# pmg1s2 register map
Vendor: Cypress Semiconductor; Series: PMG1S2; File version: 1.0
CPU: CM0 r0p1, little endian, no MPU, no FPU, 2 interrupt priority bits
Registers are 32-bit, read-write, reset 0x0 unless marked. A register's access mark holds for its fields unless they carry their own. Offsets are from the block's base; [hi:lo] are bit positions; lines under a group give offsets from that group; {n}, {i} and the like mark numbered series; 'fields as' and 'values as' point back to an identical list; <NAME> marks a mode.

## GPIO — GPIO port control/configuration
Base 0x40040000
{0x0+0x100*i} PRT[{i}] (i=0..4) group — GPIO port registers
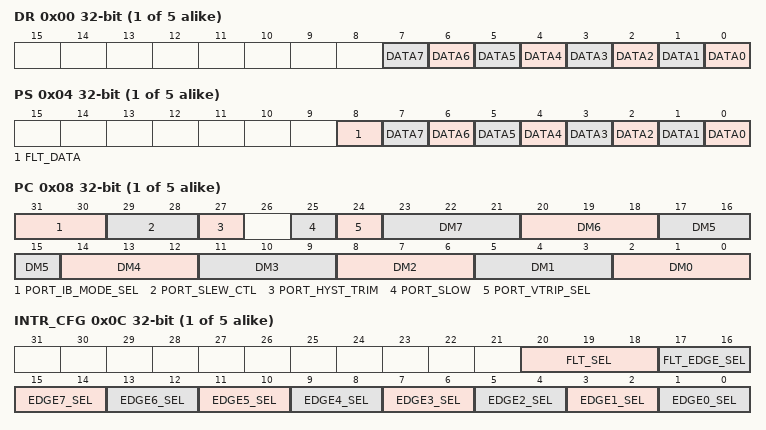
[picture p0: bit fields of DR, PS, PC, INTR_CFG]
  0x00 DR — Port output data register
    [n] DATA{n} (n=0..7) — IO pad {n} output data.
  0x04 PS ro — Port IO pad state register
    [8] FLT_DATA — Reads of this register return the logical state of the filtered pin.
    [n] DATA{n} (n=1..7) — IO pad {n} state.
    [0] DATA0 — IO pad 0 state: 1: Logic high, if the pin voltage is above the input buffer threshold, logic high. 0: Logic low, if the pin voltage is below that threshold, logic low. If the drive mode for the pin is set to high Z Analog, the pin state will read 0 independent of the voltage on the pin.
  0x08 PC — Port configuration register
    [31:30] PORT_IB_MODE_SEL — This field selects the input buffer reference. The size (1 or 2 bits) and functionality is dependent on the IO cell. For GPIOv2 IO cells, bit PORT_IB_MODE_SEL[1] is not used (GPIOv2 IO cell replaces GPIO IO cell): '0'/'2': CMOS input buffer (PORT_VTRIP_SEL is '0'), LVTTL input buffer (PORT_VTRIP_SEL is '1') '1'/'3': vcchib. For GPIO_OVTv2 and SIOv2 IO cells: '0': CMOS input buffer (PORT_VTRIP_SEL is '0'), LVTTL input buffer (PORT_VTRIP_SEL is '1') '1': vcchib. '2': OVT. '3': Reference (possibly from reference generator cell). For SIO IO cell, this field is present but not used as the SIO IO cell does not provide input buffer mode select functionality (SIOv2 IO cell will replace SIO IO cell, as soon as it is available).
    [29:28] PORT_SLEW_CTL — Slew control. Only used in the O_Z drive mode (mode 4: strong pull down, open drain): This field is intended for I2C functionality. See BROS 001-70428 for more details.
      0=HS mode (100pf < Cb < 400pF, 1.71<VDDD<5.5, Vext>3.0) FS mode (10pf<Cb<400pf,1.71<VDDD<5.5) (20-160ns); 1=HS mode (Cb<100pf,1.71<VDDD<5.5,Vext>2.8,F=1.7MHz) (10-80ns) FS+ Mode (Vext>2.8,1.71<VDDD<5.5) (20-120ns); 2=HS mode (100pf<Cb<400pf, 1.71<VDDD<5.5,Vext<3.3) (20-160ns); 3=HS mode (Cb<100pf,1.71<VDDD<5.5,Vext<=2.8,F=1.7MHz) (10-80ns) FS+ mode (Vext<=2.8,1.71<VDDD<5.5) (20-120ns)
    [27] PORT_HYST_TRIM — This field is used to improve the hysteresis (to 10 percent of vddio) of the selectable trip point input buffer. The voltage reference comes from the VREFGEN block and is only available when using the VREFGEN block: '0': <= 2.2 V input signaling Voltage. '1': > 2.2 V input signaling Voltage.
    [25] PORT_SLOW — This field controls the output edge rate of all pins on the port: '0': fast. '1': slow.
    [24] PORT_VTRIP_SEL — The GPIO cells include a VTRIP_SEL signal to alter the input buffer voltage. Note: this bit is ignored for SIO ports, the VTRIP_SEL settings in the SIO register are used instead (a separate VTRIP_SEL is provided for each pin pair). 0: input buffer functions as a CMOS input buffer. 1: input buffer functions as a LVTTL input buffer.
    [3n+2:3n] DM{n} (n=1..7) — The GPIO drive mode for IO pad {n}.
    [2:0] DM0 — The GPIO drive mode for IO pad 0. Note: when initializing IO's that are connected to a live bus (such as I2C), make sure the HSIOM is properly configured (HSIOM_PRT_SELx) before turning the IO on here to avoid producing glitches on the bus.
      0=OFF (Mode 0 (analog mode): Output buffer off (high Z). Input buffer off.); 1=INPUT (Mode 1: Output buffer off (high Z). Input buffer on.); 2=0_PU (Mode 2: Strong pull down ('0'), weak/resistive pull up (PU). Input buffer on.); 3=PD_1 (Mode 3: Weak/resistive pull down (PD), strong pull up ('1'). Input buffer on.); 4=0_Z (Mode 4: Strong pull down ('0'), open drain (pull up off). Input buffer on.); 5=Z_1 (Mode 5: Open drain (pull down off), strong pull up ('1'). Input buffer on.); 6=Mode 6: Strong pull down ('0'), strong pull up ('1'). Input buffer on.; 7=PD_PU (Mode 7: Weak/resistive pull down (PD), weak/resistive pull up (PU). Input buffer on.)
  0x0C INTR_CFG — Port interrupt configuration register
    [20:18] FLT_SEL — Selects which pin is routed through the 50ns glitch filter to provide a glitch-safe interrupt.
    [17:16] FLT_EDGE_SEL — Same for the glitch filtered pin (selected by FLT_SELECT).
      0=DISABLE (Disabled); 1=RISING (Rising edge); 2=FALLING (Falling edge); 3=BOTH (Both rising and falling edges)
    [2n+1:2n] EDGE{n}_SEL (n=1..7) — Sets which edge will trigger an IRQ for IO pad {n}.
    [1:0] EDGE0_SEL — Sets which edge will trigger an IRQ for IO pad 0.
      values as FLT_EDGE_SEL
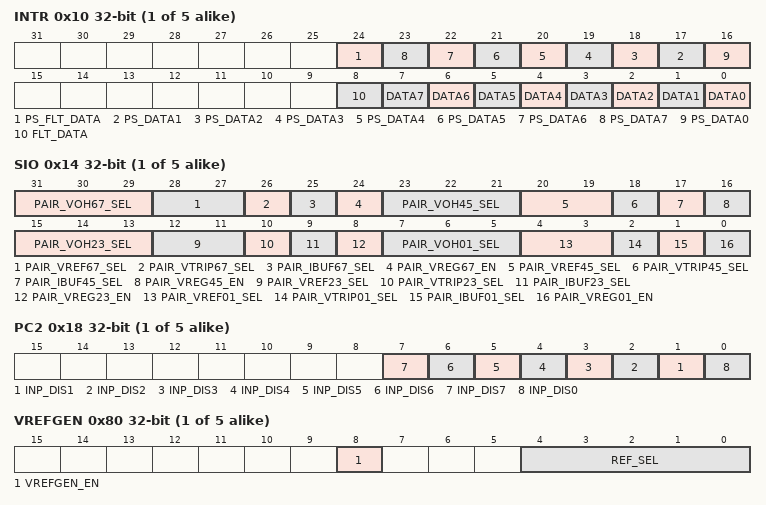
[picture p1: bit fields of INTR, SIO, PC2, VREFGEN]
  0x10 INTR — Port interrupt status register
    [24] PS_FLT_DATA ro — This is a duplicate of the contents of the PS register, provided here to allow reading of both pin state and interrupt state of the port in a single read operation.
    [n+16] PS_DATA{n} ro (n=1..7)
    [16] PS_DATA0 ro — `
    [8] FLT_DATA — Deglitched interrupt pending (selected by FLT_SELECT).
    [n] DATA{n} (n=0..7) — Interrupt pending on IO pad {n}. Firmware writes 1 to clear the interrupt.
  0x14 SIO — Port SIO configuration register
    [31:29] PAIR_VOH67_SEL — See corresponding definition for IO pads 6 and 7.
    [28:27] PAIR_VREF67_SEL — See corresponding definition for IO pads 6 and 7.
    [26] PAIR_VTRIP67_SEL — See corresponding definition for IO pads 6 and 7.
    [25] PAIR_IBUF67_SEL — See corresponding definition for IO pads 6 and 7.
    [24] PAIR_VREG67_EN — See corresponding definition for IO pads 6 and 7.
    [23:21] PAIR_VOH45_SEL — See corresponding definition for IO pads 4 and 5.
    [20:19] PAIR_VREF45_SEL — See corresponding definition for IO pads 4 and 5.
    [18] PAIR_VTRIP45_SEL — See corresponding definition for IO pads 4 and 5.
    [17] PAIR_IBUF45_SEL — See corresponding definition for IO pads 4 and 5.
    [16] PAIR_VREG45_EN — See corresponding definition for IO pads 4 and 5.
    [15:13] PAIR_VOH23_SEL — See corresponding definition for IO pads 2 and 3.
    [12:11] PAIR_VREF23_SEL — See corresponding definition for IO pads 2 and 3.
    [10] PAIR_VTRIP23_SEL — See corresponding definition for IO pads 2 and 3.
    [9] PAIR_IBUF23_SEL — See corresponding definition for IO pads 2 and 3.
    [8] PAIR_VREG23_EN — See corresponding definition for IO pads 2 and 3.
    [7:5] PAIR_VOH01_SEL — Selects regulated Voh output level and trip point of input buffer for a specific SIO pin pair. Voh depends on the selected reference voltage (VREF_SEL). 0: Voh = 1*reference; e.g. reference at 1.2V -> Voh = 1.2V 1: Voh = 1.25*reference; e.g. reference at 1.2V -> Voh = 1.5V 2: Voh = 1.49*reference; e.g. reference at 1.2V -> Voh = ~1.8V 3: Voh = 1.67*reference; e.g. reference at 1.2V -> Voh = 2V 4: Voh = 2.08*reference; e.g. reference at 1.2V -> Voh = 2.5V 5: Voh = 2.5*reference; e.g. reference at 1.2V -> Voh = 3V 6: Voh = 2.78*reference; e.g. reference at 1.2V -> Voh = ~3.3V 7: Voh = 4.16*reference; e.g. reference at 1.2V -> Voh = 5.0V Note: The upper value on VOH is limited to Vddio - 400mV
    [4:3] PAIR_VREF01_SEL — Selects reference voltage Vref for trip-point of input buffer: 0: trip-point reference of SRSS internal referece Vref (1.2V) 1: trip-point reference of SRSS internal referece Vref (1.2V) 2: trip-point reference of AMUXBUS_A 3: trip-point reference of AMUXBUS_B Please refer to s8iom0s8 BROS 001-70428, section 4.2.7 for more details.
    [2] PAIR_VTRIP01_SEL — Selects trip-point of input buffer. In single ended input buffer mode (IBUF01_SEL = '0'): 0: input buffer functions as a CMOS input buffer. 1: input buffer functions as a LVTTL input buffer. In differential input buffer mode (IBUF01_SEL = '1') '0': trip-point is 0.5*Vddio or 0.5*Voh (depends on VREF_SEL/VOH_SEL) '1': trip-point is 0.4*Vddio or 1.0*Vref (depends on VREF_SEL) Please refer to s8iom0s8 BROS 001-70428, section 4.2.7 for more details.
    [1] PAIR_IBUF01_SEL — Selects input buffer mode: 0: singled ended input buffer 1: differential input buffer
    [0] PAIR_VREG01_EN — Selects output buffer mode: 0: unregulated output buffer 1: regulated output buffer
  0x18 PC2 — Port configuration register 2
    [n] INP_DIS{n} (n=1..7) — Disables the input buffer for IO pad {n}.
    [0] INP_DIS0 — Disables the input buffer for IO pad 0 independent of the port control drive mode (PC.DM). This bit should be set when analog signals are present on the pin and PC.DM != 0 is required to use the output driver.
  0x40 DR_SET — Port output data set register
    [7:0] DATA — IO pad i: '0': Output state DR.DATA[i] not affected. '1': Output state DR.DATA[i] set to '1'.
  0x44 DR_CLR — Port output data clear register
    [7:0] DATA — IO pad i: '0': Output state DR.DATA[i] not affected. '1': Output state DR.DATA[i] set to '0'.
  0x48 DR_INV — Port output data invert register
    [7:0] DATA — IO pad i: '0': Output state DR.DATA[i] not affected. '1': Output state DR.DATA[i] inverted ('0' => '1', '1' => '0').
  0x80 VREFGEN — Reference generator configuration register
    [8] VREFGEN_EN — Reference generator enable: '0': Disabled. '1': Enabled.
    [4:0] REF_SEL — Reference selection. A reference Voltage vinref is created using a Voltage vddio: '0': vinref = (0 * 13 + 184)/600 * vddio = 184/600 * vddio. '1': vinref = (1 * 13 + 184)/600 * vddio = 197/600 * vddio. '2': vinref = (2 * 13 + 184)/600 * vddio = 210/600 * vddio. ... '31': vinref = (31 * 13 + 184)/600 * vddio = 587/600 * vddio.
0x1000 INTR_CAUSE ro — Interrupt port cause register
  [31:0] PORT_INT — Each IO port has an associated bit field in this register. The bit field reflects the IO port's interrupt line (bit field i reflects 'gpio_interrupts[i]' for IO port i). The register is used when the system uses a shared/combined interrupt line 'gpio_interrupt'. The SW ISR reads the register to deternine which IO port(s) is responsible for the shared/combined interrupt line 'gpio_interrupt'. Once, the IO port(s) is determined, the IO port's INTR register is read to determine the IO pad(s) in the IO port that caused the interrupt.

## SPCIF — Flash Control Interface
Base 0x40110000
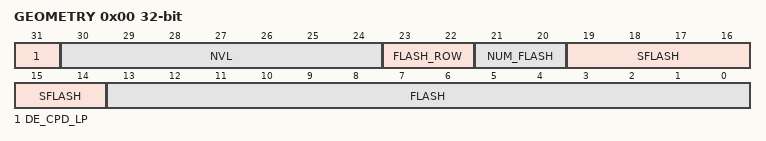
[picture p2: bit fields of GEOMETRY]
0x00 GEOMETRY (reset mask 0x80000000) — Flash/NVL geometry information
  [31] DE_CPD_LP — 0': SRAM busy wait loop has not been copied. '1': Busy wait loop has been written into SRAM.
  [30:24] NVL ro — NVLatch size in Byte multiples (chip dependent): '0': 0 Bytes '1': 1 Byte ... '127': 127 Bytes
  [23:22] FLASH_ROW ro — Page size in 64 Byte multiples (chip dependent): '0': 64 byte '1': 128 byte '2': 192 byte '3': 256 byte The page size is used to detemine the number of Bytes in a page for Flash page based operations (e.g. PGM_PAGE). Note: the field name FLASH_ROW is misleading, as this field specifies the number of Bytes in a page, rather than the number of Bytes in a row. In a single plane flash macro architecture, a page consists of a single row. However, in a multi plane flash macro architecture, a page consists of multiple rows from different planes.
  [21:20] NUM_FLASH ro — Number of flash macros (chip dependent): '0': 1 flash macro '1': 2 flash macros '2': 3 flash macros '3': 4 flash macros
  [19:14] SFLASH ro — Supervisory flash capacity in 256 Byte multiples (chip dependent). If multiple flash macros are present, this field provides the supervisory flash capacity of all flash macros together: '0': 256 Bytes. '1': 2*256 Bytes. ... '63': 64*256 Bytes.
  [13:0] FLASH ro — Regular flash capacity in 256 Byte multiples (chip dependent). If multiple flash macros are present, this field provides the flash capacity of all flash macros together: '0': 256 Bytes. '1': 2*256 Bytes. ... '16383': 16384*256 Bytes.
0x1C NVL_WR_DATA — NVL write data register
  [7:0] DATA — Data to be written to NVLatch array
0x7F0 INTR — SPCIF interrupt request register
  [0] TIMER — Timer counter value reaches '0'. Set to '1', when event is detected. Write INTR field with '1', to clear bit. Write INTR_SET field with '1', to set bit.
0x7F4 INTR_SET — SPCIF interrupt set request register
  [0] TIMER — Write INTR_SET field with '1' to set corresponding INTR field.
0x7F8 INTR_MASK — SPCIF interrupt mask register
  [0] TIMER — Mask for corresponding field in INTR register.
0x7FC INTR_MASKED ro — SPCIF interrupt masked request register
  [0] TIMER — Logical and of corresponding request and mask fields.
